# STM32F7x6 register map
File version: 1.6
CPU: CM7 r0p1, little endian, MPU, FPU, 4 interrupt priority bits
Registers are 32-bit, read-write, reset 0x0 unless marked. A register's access mark holds for its fields unless they carry their own. Offsets are from the block's base; [hi:lo] are bit positions; {n}, {i} and the like mark numbered series.

## DBGMCU — Debug support
Base 0xE0042000
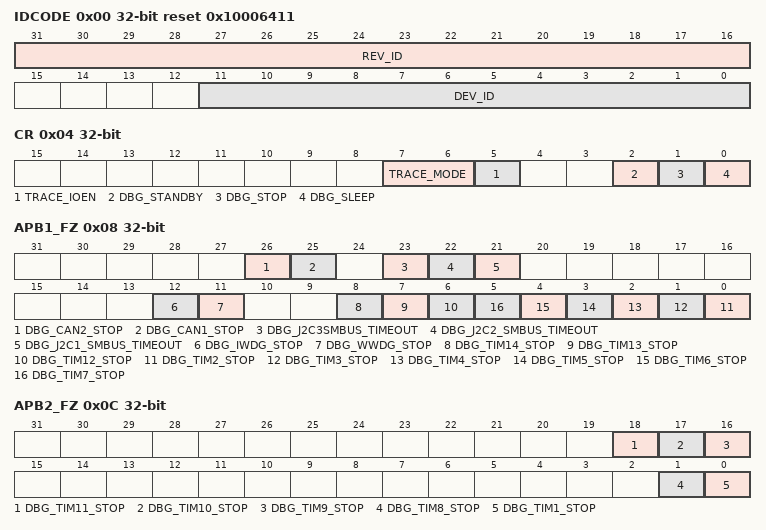
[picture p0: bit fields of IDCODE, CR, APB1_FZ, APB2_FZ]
0x00 IDCODE ro reset 0x10006411
  [31:16] REV_ID, [11:0] DEV_ID
0x04 CR — Control Register
  [7:6] TRACE_MODE, [5] TRACE_IOEN, [2] DBG_STANDBY, [1] DBG_STOP, [0] DBG_SLEEP
0x08 APB1_FZ — Debug MCU APB1 Freeze registe
  [26] DBG_CAN2_STOP
  [25] DBG_CAN1_STOP
  [23] DBG_J2C3SMBUS_TIMEOUT
  [22] DBG_J2C2_SMBUS_TIMEOUT
  [21] DBG_J2C1_SMBUS_TIMEOUT
  [12] DBG_IWDG_STOP — DBG_IWDEG_STOP
  [11] DBG_WWDG_STOP
  [8] DBG_TIM14_STOP
  [7] DBG_TIM13_STOP
  [6] DBG_TIM12_STOP
  [n-2] DBG_TIM{n}_STOP (n=2..7)
0x0C APB2_FZ — Debug MCU APB2 Freeze registe
  [18] DBG_TIM11_STOP — TIM11 counter stopped when core is halted
  [17] DBG_TIM10_STOP — TIM10 counter stopped when core is halted
  [16] DBG_TIM9_STOP — TIM9 counter stopped when core is halted
  [1] DBG_TIM8_STOP — TIM8 counter stopped when core is halted
  [0] DBG_TIM1_STOP — TIM1 counter stopped when core is halted

## GPIOA — General-purpose I/Os
Base 0x40020000
Same registers: GPIOB 0x40020400, GPIOC 0x40020800, GPIOD 0x40020C00, GPIOE 0x40021000, GPIOF 0x40021400, GPIOG 0x40021800, GPIOH 0x40021C00, GPIOI 0x40022000, GPIOJ 0x40022400, GPIOK 0x40022800
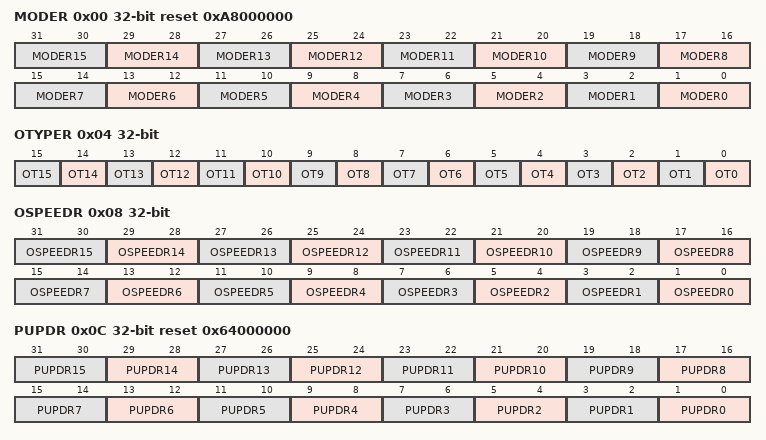
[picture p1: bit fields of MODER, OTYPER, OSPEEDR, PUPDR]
0x00 MODER reset 0xA8000000 — GPIO port mode register
  [all] fields
    0=Input mode (reset state); 1=Output (General purpose output mode); 2=Alternate function mode; 3=Analog mode
  [2n+1:2n] MODER{n} (n=0..15) — Port x configuration bits (y = 0..15)
0x04 OTYPER — GPIO port output type register
  [all] fields
    0=PushPull (Output push-pull (reset state)); 1=OpenDrain (Output open-drain)
  [n] OT{n} (n=0..15) — Port x configuration bits (y = 0..15)
0x08 OSPEEDR — GPIO port output speed register
  [all] fields
    0=LowSpeed; 1=MediumSpeed; 2=HighSpeed; 3=VeryHighSpeed
  [2n+1:2n] OSPEEDR{n} (n=0..15) — Port x configuration bits (y = 0..15)
0x0C PUPDR reset 0x64000000 — GPIO port pull-up/pull-down register
  [all] fields
    0=Floating (No pull-up, pull-down); 1=PullUp; 2=PullDown
  [2n+1:2n] PUPDR{n} (n=0..15) — Port x configuration bits (y = 0..15)
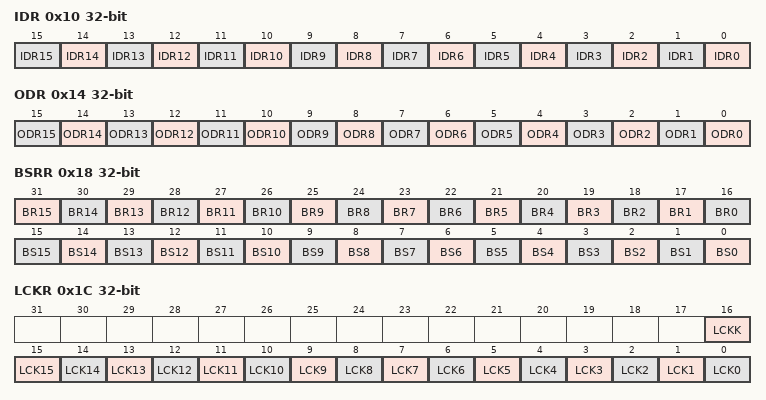
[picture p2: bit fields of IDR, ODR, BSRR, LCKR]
0x10 IDR ro — GPIO port input data register
  [all] fields
    on read: 0=Low (Input is logic low); 1=High (Input is logic high)
  [n] IDR{n} (n=0..15) — Port input data (y = 0..15)
0x14 ODR — GPIO port output data register
  [all] fields
    0=Low (Set output to logic low); 1=High (Set output to logic high)
  [n] ODR{n} (n=0..15) — Port output data (y = 0..15)
0x18 BSRR wo — GPIO port bit set/reset register
  [n+16] BR{n} (n=1..15) — Port x reset bit y (y = 0..15)
    on write: 1=Resets the corresponding ODRx bit
  [16] BR0 — Port x set bit y (y= 0..15)
    on write: 1=Resets the corresponding ODRx bit
  [n] BS{n} (n=0..15) — Port x set bit y (y= 0..15)
    on write: 1=Set (Sets the corresponding ODRx bit)
0x1C LCKR — GPIO port configuration lock register
  [16] LCKK — Port x lock bit y (y= 0..15)
    0=NotActive (Port configuration lock key not active); 1=Active (Port configuration lock key active)
  [n] LCK{n} (n=0..15) — Port x lock bit y (y= 0..15)
    0=Unlocked (Port configuration not locked); 1=Locked (Port configuration locked)
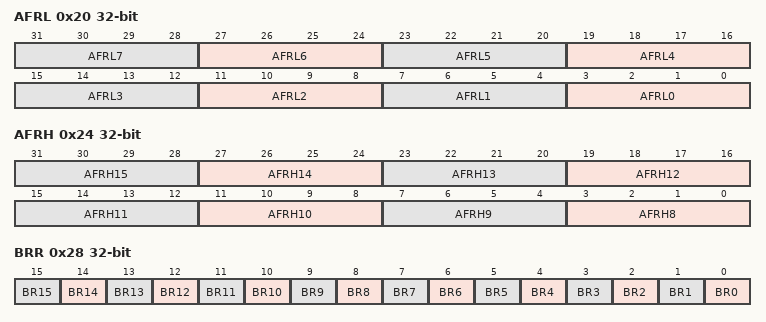
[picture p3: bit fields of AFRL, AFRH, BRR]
0x20 AFRL — GPIO alternate function low register
  [all] fields
    {v}=AF{v} (v=0..15)
  [4n+3:4n] AFRL{n} (n=0..7) — Alternate function selection for port x bit y (y = 0..7)
0x24 AFRH — GPIO alternate function high register
  [all] fields
    {v}=AF{v} (v=0..15)
  [4n-29:4n-32] AFRH{n} (n=8..15) — Alternate function selection for port x bit y (y = 8..15)
0x28 BRR — GPIO port bit reset register
  [n] BR{n} (n=0..15) — Port A Reset bit {n}

## SYSCFG — System configuration controller
Base 0x40013800
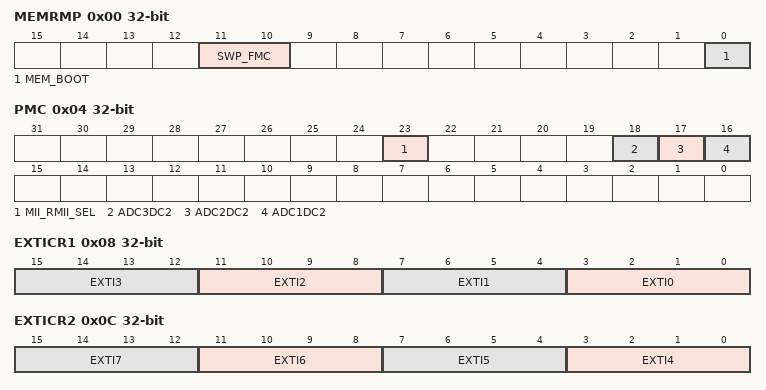
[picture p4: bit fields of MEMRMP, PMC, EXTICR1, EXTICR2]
0x00 MEMRMP — memory remap register
  [11:10] SWP_FMC — FMC memory mapping swap
  [0] MEM_BOOT — Memory mapping selection
0x04 PMC — peripheral mode configuration register
  [23] MII_RMII_SEL — Ethernet PHY interface selection
  [18] ADC3DC2
  [17] ADC2DC2
  [16] ADC1DC2
0x08 EXTICR1 — external interrupt configuration register 1
  [4n+3:4n] EXTI{n} (n=0..3) — EXTI x configuration (x = 0 to 3)
0x0C EXTICR2 — external interrupt configuration register 2
  [4n-13:4n-16] EXTI{n} (n=4..7) — EXTI x configuration (x = 4 to 7)
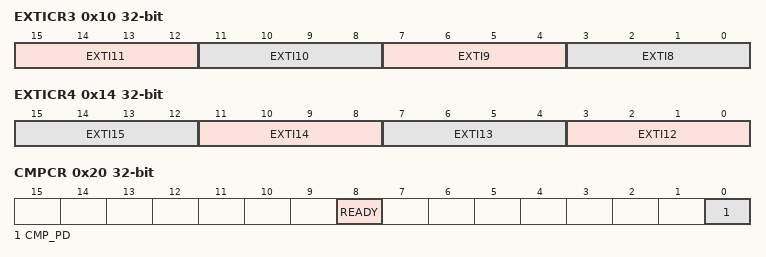
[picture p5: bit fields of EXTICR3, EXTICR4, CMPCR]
0x10 EXTICR3 — external interrupt configuration register 3
  [15:12] EXTI11 — EXTI x configuration (x = 8 to 11)
  [11:8] EXTI10
  [7:4] EXTI9 — EXTI x configuration (x = 8 to 11)
  [3:0] EXTI8 — EXTI x configuration (x = 8 to 11)
0x14 EXTICR4 — external interrupt configuration register 4
  [4n-45:4n-48] EXTI{n} (n=12..15) — EXTI x configuration (x = 12 to 15)
0x20 CMPCR ro — Compensation cell control register
  [8] READY
  [0] CMP_PD — Compensation cell power-down
